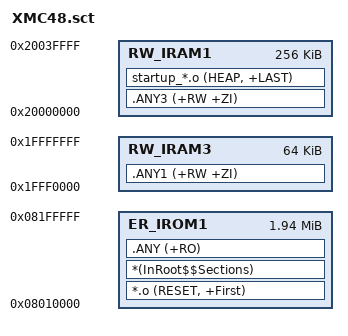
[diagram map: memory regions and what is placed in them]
; *************************************************************
; *** Scatter-Loading Description File generated by uVision ***
; *************************************************************

LR_IROM1 0x08010000 0x001F0000  {    ; load region size_region
  ER_IROM1 0x08010000 0x001F0000  {  ; load address = execution address
   *.o (RESET, +First)
   *(InRoot$$Sections)
   ;startup_*.o (+RO)
   .ANY (+RO)
  }

  RW_IRAM1 0x20000000 0x40000  {  ; RW data
   .ANY3 (+RW +ZI)
   startup_*.o (HEAP, +LAST)
  }

  RW_IRAM3 0x1FFF0000 0x10000  {  ; RO data
   .ANY1 (+RW +ZI)
  }

}

